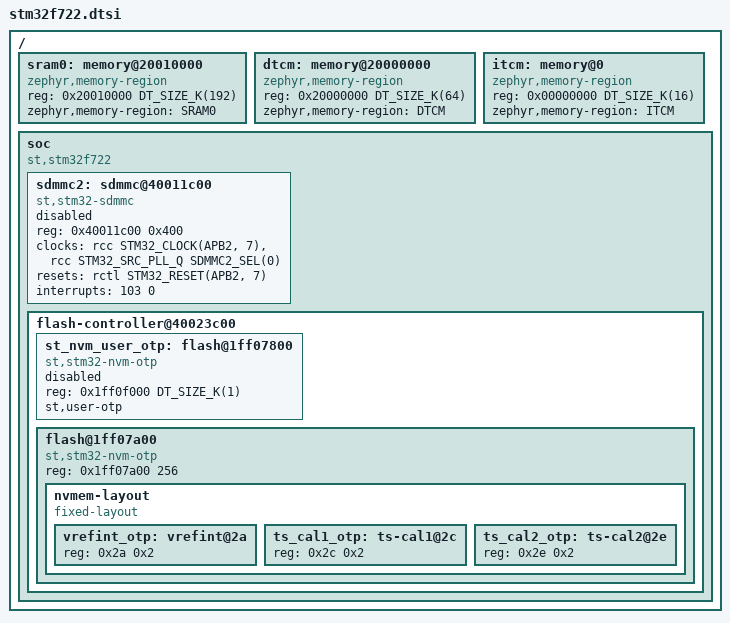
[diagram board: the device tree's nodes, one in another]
/*
 * Copyright (c) 2023 Evan Perry Grove
 *
 * SPDX-License-Identifier: Apache-2.0
 */

#include <st/f7/stm32f7.dtsi>

/ {
	/* 16KB ITCM @ 0x0, 64KB DTCM @ 0x20000000,
	 * 176KB SRAM1 @ 0x20010000, 16KB SRAM2 @ 0x2003C00
	 */

	sram0: memory@20010000 {
		compatible = "zephyr,memory-region", "mmio-sram";
		reg = <0x20010000 DT_SIZE_K(192)>;
		zephyr,memory-region = "SRAM0";
	};

	dtcm: memory@20000000 {
		compatible = "zephyr,memory-region", "arm,dtcm";
		reg = <0x20000000 DT_SIZE_K(64)>;
		zephyr,memory-region = "DTCM";
	};

	itcm: memory@0 {
		compatible = "zephyr,memory-region", "arm,itcm";
		reg = <0x00000000 DT_SIZE_K(16)>;
		zephyr,memory-region = "ITCM";
	};

	soc {
		compatible = "st,stm32f722", "st,stm32f7", "simple-bus";

		sdmmc2: sdmmc@40011c00 {
			compatible = "st,stm32-sdmmc";
			reg = <0x40011c00 0x400>;
			clocks = <&rcc STM32_CLOCK(APB2, 7)>,
				 <&rcc STM32_SRC_PLL_Q SDMMC2_SEL(0)>;
			resets = <&rctl STM32_RESET(APB2, 7)>;
			interrupts = <103 0>;
			status = "disabled";
		};

		flash-controller@40023c00 {
			/*
			 * Delete OTP regions declared in root DTSI
			 * which are not correct for this product line.
			 */
			/delete-node/ flash@1ff0f000;
			/delete-node/ flash@1ff0f400;

			st_nvm_user_otp: flash@1ff07800 {
				compatible = "st,stm32-nvm-otp";
				reg = <0x1ff0f000 DT_SIZE_K(1)>;
				status = "disabled";

				st,user-otp;
			};

			/* c.f. root DTSI file - same comment applies */
			flash@1ff07a00 {
				compatible = "st,stm32-nvm-otp";
				reg = <0x1ff07a00 256>;

				nvmem-layout {
					compatible = "fixed-layout";
					#address-cells = <1>;
					#size-cells = <1>;

					vrefint_otp: vrefint@2a {
						reg = <0x2a 0x2>;
						#nvmem-cell-cells = <0>;
					};

					ts_cal1_otp: ts-cal1@2c {
						reg = <0x2c 0x2>;
						#nvmem-cell-cells = <0>;
					};

					ts_cal2_otp: ts-cal2@2e {
						reg = <0x2e 0x2>;
						#nvmem-cell-cells = <0>;
					};
				};
			};
		};
	};
};
